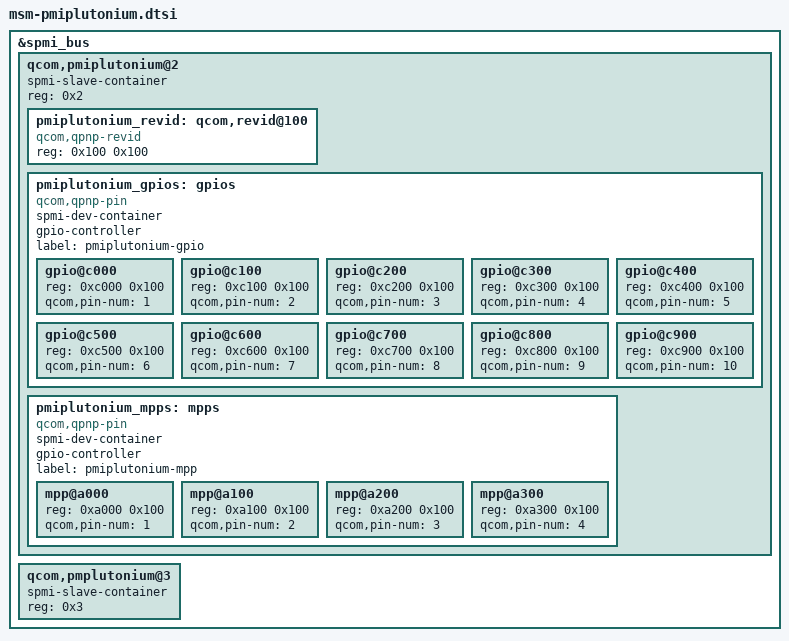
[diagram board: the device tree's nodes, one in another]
/* Copyright (c) 2014, The Linux Foundation. All rights reserved.
 *
 * This program is free software; you can redistribute it and/or modify
 * it under the terms of the GNU General Public License version 2 and
 * only version 2 as published by the Free Software Foundation.
 *
 * This program is distributed in the hope that it will be useful,
 * but WITHOUT ANY WARRANTY; without even the implied warranty of
 * MERCHANTABILITY or FITNESS FOR A PARTICULAR PURPOSE.  See the
 * GNU General Public License for more details.
 */

&spmi_bus {
	qcom,pmiplutonium@2 {
		spmi-slave-container;
		#address-cells = <1>;
		#size-cells = <1>;
		reg = <0x2>;

		pmiplutonium_revid: qcom,revid@100 {
			compatible = "qcom,qpnp-revid";
			reg = <0x100 0x100>;
		};

		pmiplutonium_gpios: gpios {
			spmi-dev-container;
			compatible = "qcom,qpnp-pin";
			gpio-controller;
			#gpio-cells = <2>;
			#address-cells = <1>;
			#size-cells = <1>;
			label = "pmiplutonium-gpio";

			gpio@c000 {
				reg = <0xc000 0x100>;
				qcom,pin-num = <1>;
			};

			gpio@c100 {
				reg = <0xc100 0x100>;
				qcom,pin-num = <2>;
			};

			gpio@c200 {
				reg = <0xc200 0x100>;
				qcom,pin-num = <3>;
			};

			gpio@c300 {
				reg = <0xc300 0x100>;
				qcom,pin-num = <4>;
			};

			gpio@c400 {
				reg = <0xc400 0x100>;
				qcom,pin-num = <5>;
			};

			gpio@c500 {
				reg = <0xc500 0x100>;
				qcom,pin-num = <6>;
			};

			gpio@c600 {
				reg = <0xc600 0x100>;
				qcom,pin-num = <7>;
			};

			gpio@c700 {
				reg = <0xc700 0x100>;
				qcom,pin-num = <8>;
			};

			gpio@c800 {
				reg = <0xc800 0x100>;
				qcom,pin-num = <9>;
			};

			gpio@c900 {
				reg = <0xc900 0x100>;
				qcom,pin-num = <10>;
			};
		};

		pmiplutonium_mpps: mpps {
			spmi-dev-container;
			compatible = "qcom,qpnp-pin";
			gpio-controller;
			#gpio-cells = <2>;
			#address-cells = <1>;
			#size-cells = <1>;
			label = "pmiplutonium-mpp";

			mpp@a000 {
				reg = <0xa000 0x100>;
				qcom,pin-num = <1>;
			};

			mpp@a100 {
				reg = <0xa100 0x100>;
				qcom,pin-num = <2>;
			};

			mpp@a200 {
				reg = <0xa200 0x100>;
				qcom,pin-num = <3>;
			};

			mpp@a300 {
				reg = <0xa300 0x100>;
				qcom,pin-num = <4>;
			};
		};
	};

	qcom,pmplutonium@3 {
		spmi-slave-container;
		#address-cells = <1>;
		#size-cells = <1>;
		reg = <0x3>;
	};
};
